# CM_CORE__L3INIT register map
Vendor: Texas Instruments
Peripheral module from a debugger description file (folder DRA74xP_75xP_76xP_77xP).
Registers are 32-bit, access per field, reset 0x70000 unless marked. A register's access mark holds for its fields unless they carry their own. Offsets are as the file gives them; lines under a group give offsets from that group; [hi:lo] are bit positions; {n}, {i} and the like mark numbered series; 'fields as' and 'values as' point back to an identical list; <NAME> marks a mode.

## CM_CORE__L3INIT
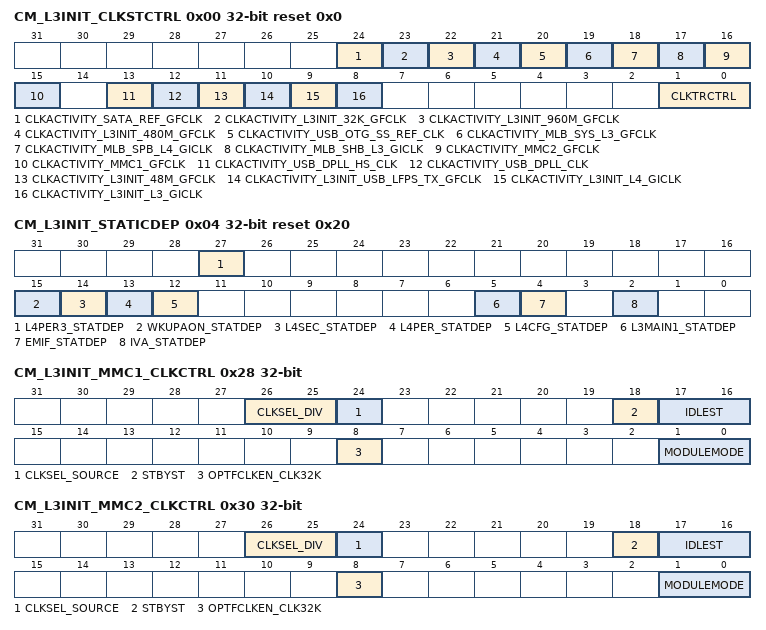
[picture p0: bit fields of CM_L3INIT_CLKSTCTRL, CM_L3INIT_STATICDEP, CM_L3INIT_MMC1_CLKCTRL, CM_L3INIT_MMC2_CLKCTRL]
0x00 CM_L3INIT_CLKSTCTRL reset 0x0 — This register enables the domain power state transition. It controls the HW supervised domain power state transition between ON-ACTIVE and ON-INACTIVE states. It also hold one status bit per clock input of the domain.
  [24] CLKACTIVITY_SATA_REF_GFCLK ro — This field indicates the state of the SATA_REF_GFCLK clock in the domain. [warm reset insensitive]
    0=INACT (Corresponding clock is definitely gated); 1=ACT (Corresponding clock is running or gating/ungating transition is on-going)
  [23] CLKACTIVITY_L3INIT_32K_GFCLK ro — This field indicates the state of the L3INIT_32K_FCLK clock in the domain. [warm reset insensitive]
    values as CLKACTIVITY_SATA_REF_GFCLK
  [22] CLKACTIVITY_L3INIT_960M_GFCLK ro — This field indicates the state of the L3INIT_960M_GFCLK clock in the domain. [warm reset insensitive]
    values as CLKACTIVITY_SATA_REF_GFCLK
  [21] CLKACTIVITY_L3INIT_480M_GFCLK ro — This field indicates the state of the L3INIT_480M_GFCLK clock in the domain. [warm reset insensitive]
    values as CLKACTIVITY_SATA_REF_GFCLK
  [20] CLKACTIVITY_USB_OTG_SS_REF_CLK ro — This field indicates the state of the USB_OTG_SS_REF_CLK clock in the domain. [warm reset insensitive]
    values as CLKACTIVITY_SATA_REF_GFCLK
  [19] CLKACTIVITY_MLB_SYS_L3_GFCLK ro — This field indicates the state of the MLB_SYS_L3_GFCLK clock in the domain. [warm reset insensitive]
    values as CLKACTIVITY_SATA_REF_GFCLK
  [18] CLKACTIVITY_MLB_SPB_L4_GICLK ro — This field indicates the state of the MLB_SPB_L4_GICLK clock in the domain. [warm reset insensitive]
    values as CLKACTIVITY_SATA_REF_GFCLK
  [17] CLKACTIVITY_MLB_SHB_L3_GICLK ro — This field indicates the state of the MLB_SHB_L3_GICLK clock in the domain. [warm reset insensitive]
    values as CLKACTIVITY_SATA_REF_GFCLK
  [16] CLKACTIVITY_MMC2_GFCLK ro — This field indicates the state of the MMC2 clock in the domain. [warm reset insensitive]
    values as CLKACTIVITY_SATA_REF_GFCLK
  [15] CLKACTIVITY_MMC1_GFCLK ro — This field indicates the state of the MMC1_GFCLK clock in the domain. [warm reset insensitive]
    values as CLKACTIVITY_SATA_REF_GFCLK
  [13] CLKACTIVITY_USB_DPLL_HS_CLK ro — This field indicates the state of the USB_DPLL_HS_CLK clock in the domain. [warm reset insensitive]
    values as CLKACTIVITY_SATA_REF_GFCLK
  [12] CLKACTIVITY_USB_DPLL_CLK ro — This field indicates the state of the USB_DPLL_CLK clock in the domain. [warm reset insensitive]
    values as CLKACTIVITY_SATA_REF_GFCLK
  [11] CLKACTIVITY_L3INIT_48M_GFCLK ro — This field indicates the state of the INIT_48M_GFCLK clock in the domain. [warm reset insensitive]
    values as CLKACTIVITY_SATA_REF_GFCLK
  [10] CLKACTIVITY_L3INIT_USB_LFPS_TX_GFCLK ro — This field indicates the state of the L3INIT_USB_LFPS_TX_GFCLK clock in the domain. [warm reset insensitive]
    values as CLKACTIVITY_SATA_REF_GFCLK
  [9] CLKACTIVITY_L3INIT_L4_GICLK ro — This field indicates the state of the L3INIT_L4_GICLK clock in the domain. [warm reset insensitive]
    values as CLKACTIVITY_SATA_REF_GFCLK
  [8] CLKACTIVITY_L3INIT_L3_GICLK ro — This field indicates the state of the L3INIT_L3_GICLK clock in the domain. [warm reset insensitive]
    values as CLKACTIVITY_SATA_REF_GFCLK
  [1:0] CLKTRCTRL rw — Controls the clock state transition of the L3INIT clock domain.
    0=NO_SLEEP (NO_SLEEP: Sleep transition cannot be initiated. Wakeup transition may however occur.); 1=SW_SLEEP (SW_SLEEP: Start a software forced sleep transition on the domain.); 2=SW_WKUP (SW_WKUP: Start a software forced wake-up transition on the domain.); 3=HW_AUTO (HW_AUTO: Automatic transition is enabled. Sleep and wakeup transition are based upon hardware conditions.)
0x04 CM_L3INIT_STATICDEP reset 0x20 — This register controls the static domain depedencies from L3INIT domain towards 'target' domains. It is relevant only for domain having system initiator(s).
  [27] L4PER3_STATDEP rw — Static dependency towards L4PER3 clock domain
    0=DISABLED (Dependency is disabled); 1=ENABLED (Dependency is enabled)
  [15] WKUPAON_STATDEP rw — Static dependency towards WKUPAON clock domain
    values as L4PER3_STATDEP
  [14] L4SEC_STATDEP rw — Static dependency towards L4SEC clock domain
    values as L4PER3_STATDEP
  [13] L4PER_STATDEP rw — Static dependency towards L4PER1 clock domain
    values as L4PER3_STATDEP
  [12] L4CFG_STATDEP rw — Static dependency towards L4CFG clock domain
    values as L4PER3_STATDEP
  [5] L3MAIN1_STATDEP ro — Static dependency towards L3MAIN1 clock domain
    1=ENABLED (Dependency is enabled)
  [4] EMIF_STATDEP rw — Static dependency towards EMIF clock domain
    values as L4PER3_STATDEP
  [2] IVA_STATDEP rw — Static dependency towards IVA clock domain
    values as L4PER3_STATDEP
0x08 CM_L3INIT_DYNAMICDEP ro reset 0x0 — This register controls the dynamic domain depedencies from L3INIT domain towards 'target' domains. It is relevant only for domain having OCP master port(s).
  [5] L3MAIN1_DYNDEP — Dynamic dependency towards L3MAIN1 clock domain
    0=DISABLED (Dependency is Disabled)
0x28 CM_L3INIT_MMC1_CLKCTRL — This register manages the MMC1 clocks.
  [26:25] CLKSEL_DIV rw — MMC1 clock divide ratio.
    0=DIV1 (MMC1 clock is divided by 1.); 1=DIV2 (MMC1 clock is divided by 2.); 2=DIV4 (MMC1 clock is divided by 4.)
  [24] CLKSEL_SOURCE rw — Selects the source of the functional clock.
    0=SEL_128M (128MHz clock derived from DPLL_PER is selected); 1=SEL_192M (192MHz clock derived from DPLL_PER is selected)
  [18] STBYST ro — Module standby status. [warm reset insensitive]
    0=FUNC (Module is functional (not in standby)); 1=STANDBY (Module is in standby)
  [17:16] IDLEST ro — Module idle status. [warm reset insensitive]
    0=FUNC (Module is fully functional, including OCP); 1=TRANS (Module is performing transition: wakeup, or sleep, or sleep abortion); 2=IDLE (Module is in Idle mode (only OCP part). It is functional if using separate functional clock); 3=DISABLE (Module is disabled and cannot be accessed)
  [8] OPTFCLKEN_CLK32K rw — MMC optional clock control: 32K CLK
    0=FCLK_DIS (Optional functional clock is disabled); 1=FCLK_EN (Optional functional clock is enabled)
  [1:0] MODULEMODE rw — Control the way mandatory clocks are managed.
    0=DISABLED (Module is disabled by SW. Any OCP access to module results in an error, except if resulting from a module wakeup (asynchronous wakeup).); 2=ENABLED (Module is explicitly enabled. Interface clock (if not used for functions) may be gated according to the clock domain state. Functional clocks are guarantied to stay present. As long as in this configuration, power domain sleep transition cannot happen.)
0x30 CM_L3INIT_MMC2_CLKCTRL — This register manages the MMC2 clocks.
  [26:25] CLKSEL_DIV rw — MMC2 clock divide ratio
    0=DIV1 (MMC2 clock is divided by 1.); 1=DIV2 (MMC2 clock is divided by 2.); 2=DIV4 (MMC2 clock is divided by 4.)
  [24] CLKSEL_SOURCE rw — Selects the source of the functional clock.
    values as CM_L3INIT_MMC1_CLKCTRL.CLKSEL_SOURCE
  [18] STBYST ro — Module standby status. [warm reset insensitive]
    values as CM_L3INIT_MMC1_CLKCTRL.STBYST
  [17:16] IDLEST ro — Module idle status. [warm reset insensitive]
    values as CM_L3INIT_MMC1_CLKCTRL.IDLEST
  [8] OPTFCLKEN_CLK32K rw — MMC optional clock control: 32K CLK
    values as CM_L3INIT_MMC1_CLKCTRL.OPTFCLKEN_CLK32K
  [1:0] MODULEMODE rw — Control the way mandatory clocks are managed.
    values as CM_L3INIT_MMC1_CLKCTRL.MODULEMODE
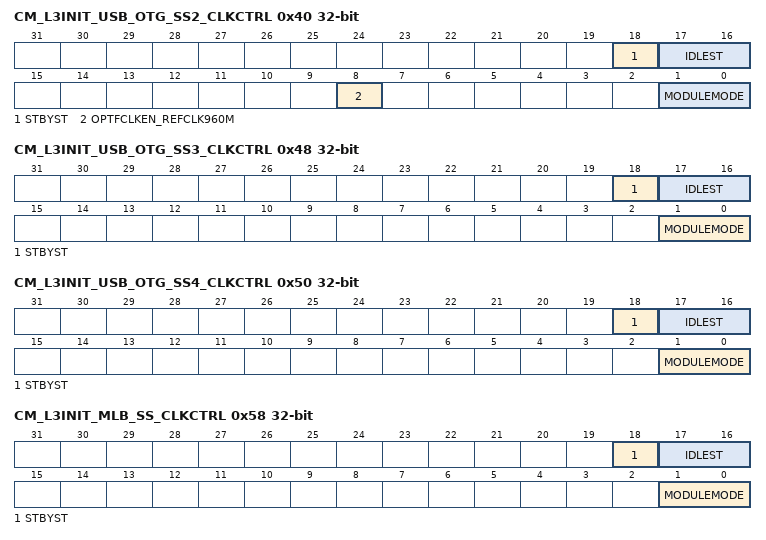
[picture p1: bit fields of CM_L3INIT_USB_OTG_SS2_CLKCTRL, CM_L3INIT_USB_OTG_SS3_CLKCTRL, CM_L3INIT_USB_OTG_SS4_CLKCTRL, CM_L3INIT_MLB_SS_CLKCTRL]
0x40 CM_L3INIT_USB_OTG_SS2_CLKCTRL — This register manages the USB_OTG_SS2 clocks.
  [18] STBYST ro — Module standby status. [warm reset insensitive]
    values as CM_L3INIT_MMC1_CLKCTRL.STBYST
  [17:16] IDLEST ro — Module idle status. [warm reset insensitive]
    values as CM_L3INIT_MMC1_CLKCTRL.IDLEST
  [8] OPTFCLKEN_REFCLK960M rw — USB_OTG_SS optional clock control: REFCLK960M (960MHz clock)
    values as CM_L3INIT_MMC1_CLKCTRL.OPTFCLKEN_CLK32K
  [1:0] MODULEMODE rw — Control the way mandatory clocks are managed.
    0=DISABLED (Module is disabled by SW. Any OCP access to module results in an error, except if resulting from a module wakeup (asynchronous wakeup).); 1=AUTO (Module is managed automatically by HW according to clock domain transition. A clock domain sleep transition put module into idle. A wakeup domain transition put it back into function. If CLKTRCTRL=3, any OCP access to module is always granted. Module clocks may be gated according to the clock domain state.)
0x48 CM_L3INIT_USB_OTG_SS3_CLKCTRL — This register manages the USB_OTG_SS3 clocks.
  [18] STBYST ro — Module standby status. [warm reset insensitive]
    values as CM_L3INIT_MMC1_CLKCTRL.STBYST
  [17:16] IDLEST ro — Module idle status. [warm reset insensitive]
    values as CM_L3INIT_MMC1_CLKCTRL.IDLEST
  [1:0] MODULEMODE rw — Control the way mandatory clocks are managed.
    values as CM_L3INIT_USB_OTG_SS2_CLKCTRL.MODULEMODE
0x50 CM_L3INIT_USB_OTG_SS4_CLKCTRL — This register manages the USB_OTG_SS4 clocks.
  fields as CM_L3INIT_USB_OTG_SS3_CLKCTRL
0x58 CM_L3INIT_MLB_SS_CLKCTRL — This register manages the MLBSS clocks.
  [18] STBYST ro — Module standby status. [warm reset insensitive]
    values as CM_L3INIT_MMC1_CLKCTRL.STBYST
  [17:16] IDLEST ro — Module idle status. [warm reset insensitive]
    values as CM_L3INIT_MMC1_CLKCTRL.IDLEST
  [1:0] MODULEMODE rw — Control the way mandatory clocks are managed.
    values as CM_L3INIT_MMC1_CLKCTRL.MODULEMODE
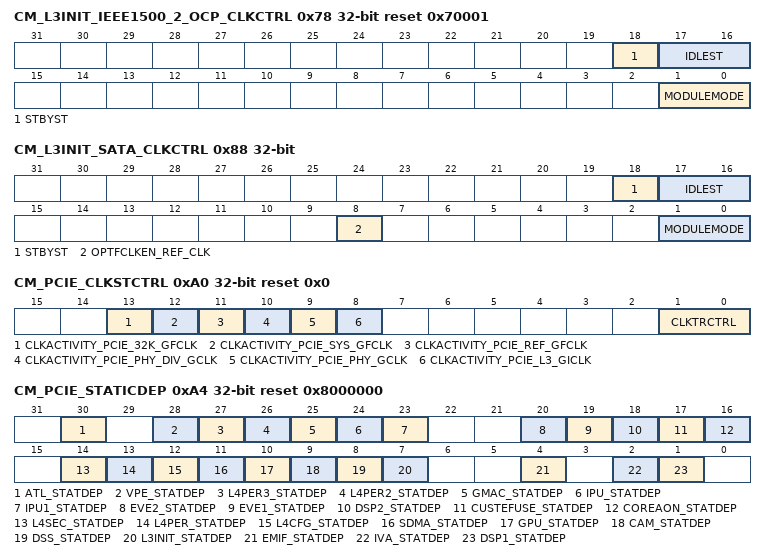
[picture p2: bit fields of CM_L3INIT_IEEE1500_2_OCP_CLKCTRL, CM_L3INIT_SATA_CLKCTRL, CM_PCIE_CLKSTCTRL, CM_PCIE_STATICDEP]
0x78 CM_L3INIT_IEEE1500_2_OCP_CLKCTRL ro reset 0x70001 — This register manages the IEE1500_2_OCP clocks.
  [18] STBYST — Module standby status. [warm reset insensitive]
    values as CM_L3INIT_MMC1_CLKCTRL.STBYST
  [17:16] IDLEST — Module idle status. [warm reset insensitive]
    values as CM_L3INIT_MMC1_CLKCTRL.IDLEST
  [1:0] MODULEMODE — Control the way mandatory clocks are managed.
    1=AUTO (Module is managed automatically by HW according to clock domain transition. A clock domain sleep transition put module into idle. A wakeup domain transition put it back into function. If CLKTRCTRL=3, any OCP access to module is always granted. Module clocks may be gated according to the clock domain state.)
0x88 CM_L3INIT_SATA_CLKCTRL — This register manages the SATA clocks.
  [18] STBYST ro — Module standby status. [warm reset insensitive]
    values as CM_L3INIT_MMC1_CLKCTRL.STBYST
  [17:16] IDLEST ro — Module idle status. [warm reset insensitive]
    values as CM_L3INIT_MMC1_CLKCTRL.IDLEST
  [8] OPTFCLKEN_REF_CLK rw — SATA optional clock control: REF_CLK (from SYS_CLK clock)
    values as CM_L3INIT_MMC1_CLKCTRL.OPTFCLKEN_CLK32K
  [1:0] MODULEMODE rw — Control the way mandatory clocks are managed.
    values as CM_L3INIT_MMC1_CLKCTRL.MODULEMODE
0xA0 CM_PCIE_CLKSTCTRL reset 0x0 — This register enables the domain power state transition. It controls the HW supervised domain power state transition between ON-ACTIVE and ON-INACTIVE states. It also hold one status bit per clock input of the domain.
  [13] CLKACTIVITY_PCIE_32K_GFCLK ro — This field indicates the state of the PCIE_32K_GFCLK clock in the domain. [warm reset insensitive]
    values as CM_L3INIT_CLKSTCTRL.CLKACTIVITY_SATA_REF_GFCLK
  [12] CLKACTIVITY_PCIE_SYS_GFCLK ro — This field indicates the state of the PCIE_SYS_GFCLK clock in the domain. [warm reset insensitive]
    values as CM_L3INIT_CLKSTCTRL.CLKACTIVITY_SATA_REF_GFCLK
  [11] CLKACTIVITY_PCIE_REF_GFCLK ro — This field indicates the state of the PCIE_REF_GFCLK clock in the domain. [warm reset insensitive]
    values as CM_L3INIT_CLKSTCTRL.CLKACTIVITY_SATA_REF_GFCLK
  [10] CLKACTIVITY_PCIE_PHY_DIV_GCLK ro — This field indicates the state of the PCIE_PHY_DIV_GCLK clock in the domain. [warm reset insensitive]
    values as CM_L3INIT_CLKSTCTRL.CLKACTIVITY_SATA_REF_GFCLK
  [9] CLKACTIVITY_PCIE_PHY_GCLK ro — This field indicates the state of the PCIE_PHY_GCLK clock in the domain. [warm reset insensitive]
    values as CM_L3INIT_CLKSTCTRL.CLKACTIVITY_SATA_REF_GFCLK
  [8] CLKACTIVITY_PCIE_L3_GICLK ro — This field indicates the state of the PCIE_L3_GICLK clock in the domain. [warm reset insensitive]
    values as CM_L3INIT_CLKSTCTRL.CLKACTIVITY_SATA_REF_GFCLK
  [1:0] CLKTRCTRL rw — Controls the clock state transition of the L3INIT clock domain.
    values as CM_L3INIT_CLKSTCTRL.CLKTRCTRL
0xA4 CM_PCIE_STATICDEP reset 0x8000000 — This register controls the static domain depedencies from PCIE domain towards 'target' domains. It is relevant only for domain having system initiator(s).
  [30] ATL_STATDEP rw — Static dependency towards ATL clock domain
    values as CM_L3INIT_STATICDEP.L4PER3_STATDEP
  [28] VPE_STATDEP rw — Static dependency towards VPE clock domain
    values as CM_L3INIT_STATICDEP.L4PER3_STATDEP
  [27] L4PER3_STATDEP rw — Static dependency towards L4PER3 clock domain
    values as CM_L3INIT_STATICDEP.L4PER3_STATDEP
  [26] L4PER2_STATDEP rw — Static dependency towards L4PER2 clock domain
    values as CM_L3INIT_STATICDEP.L4PER3_STATDEP
  [25] GMAC_STATDEP rw — Static dependency towards GMAC clock domain
    values as CM_L3INIT_STATICDEP.L4PER3_STATDEP
  [24] IPU_STATDEP rw — Static dependency towards IPU clock domain
    values as CM_L3INIT_STATICDEP.L4PER3_STATDEP
  [23] IPU1_STATDEP rw — Static dependency towards IPU1 clock domain
    values as CM_L3INIT_STATICDEP.L4PER3_STATDEP
  [20] EVE2_STATDEP rw — Static dependency towards EVE2 clock domain
    values as CM_L3INIT_STATICDEP.L4PER3_STATDEP
  [19] EVE1_STATDEP rw — Static dependency towards EVE1 clock domain
    values as CM_L3INIT_STATICDEP.L4PER3_STATDEP
  [18] DSP2_STATDEP rw — Static dependency towards DSP2 clock domain
    values as CM_L3INIT_STATICDEP.L4PER3_STATDEP
  [17] CUSTEFUSE_STATDEP ro — Static dependency towards CUSTEFUSE clock domain
    0=DISABLED (Dependency is disabled)
  [16] COREAON_STATDEP ro — Static dependency towards COREAON clock domain
    0=DISABLED (Dependency is disabled)
  [14] L4SEC_STATDEP rw — Static dependency towards L4SEC clock domain
    values as CM_L3INIT_STATICDEP.L4PER3_STATDEP
  [13] L4PER_STATDEP rw — Static dependency towards L4PER clock domain
    values as CM_L3INIT_STATICDEP.L4PER3_STATDEP
  [12] L4CFG_STATDEP rw — Static dependency towards L4CFG clock domain
    values as CM_L3INIT_STATICDEP.L4PER3_STATDEP
  [11] SDMA_STATDEP ro — Static dependency towards SDMA clock domain
    0=DISABLED (Dependency is disabled)
  [10] GPU_STATDEP rw — Static dependency towards GPU clock domain
    values as CM_L3INIT_STATICDEP.L4PER3_STATDEP
  [9] CAM_STATDEP rw — Static dependency towards CAM clock domain
    values as CM_L3INIT_STATICDEP.L4PER3_STATDEP
  [8] DSS_STATDEP rw — Static dependency towards DSS clock domain
    values as CM_L3INIT_STATICDEP.L4PER3_STATDEP
  [7] L3INIT_STATDEP rw — Static dependency towards L3INIT clock domain
    values as CM_L3INIT_STATICDEP.L4PER3_STATDEP
  [4] EMIF_STATDEP rw — Static dependency towards EMIF clock domain
    values as CM_L3INIT_STATICDEP.L4PER3_STATDEP
  [2] IVA_STATDEP rw — Static dependency towards IVA clock domain
    values as CM_L3INIT_STATICDEP.L4PER3_STATDEP
  [1] DSP1_STATDEP rw — Static dependency towards DSP1 clock domain
    values as CM_L3INIT_STATICDEP.L4PER3_STATDEP
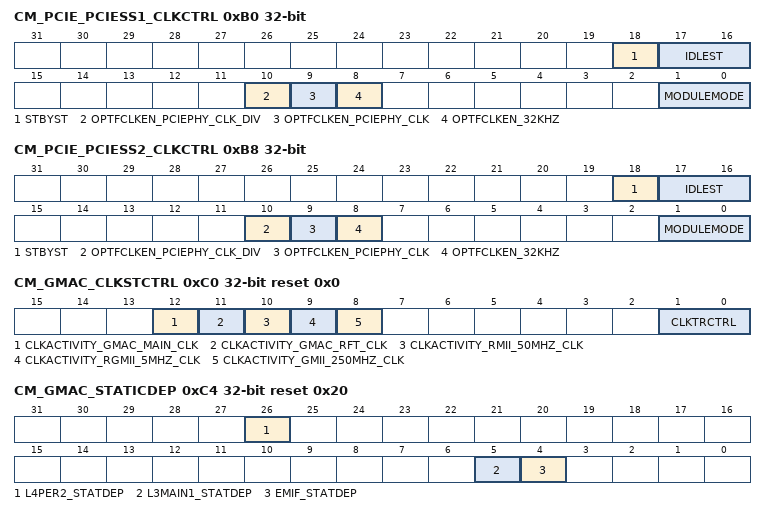
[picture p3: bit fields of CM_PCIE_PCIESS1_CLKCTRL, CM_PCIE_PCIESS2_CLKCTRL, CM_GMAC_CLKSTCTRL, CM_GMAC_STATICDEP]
0xB0 CM_PCIE_PCIESS1_CLKCTRL — This register manages the PCESS1 clocks.
  [18] STBYST ro — Module standby status. [warm reset insensitive]
    values as CM_L3INIT_MMC1_CLKCTRL.STBYST
  [17:16] IDLEST ro — Module idle status. [warm reset insensitive]
    values as CM_L3INIT_MMC1_CLKCTRL.IDLEST
  [10] OPTFCLKEN_PCIEPHY_CLK_DIV rw — PCIE PHY optional clock control
    values as CM_L3INIT_MMC1_CLKCTRL.OPTFCLKEN_CLK32K
  [9] OPTFCLKEN_PCIEPHY_CLK rw — PCIE PHY optional clock control
    values as CM_L3INIT_MMC1_CLKCTRL.OPTFCLKEN_CLK32K
  [8] OPTFCLKEN_32KHZ rw — PCIE PHY optional clock control
    values as CM_L3INIT_MMC1_CLKCTRL.OPTFCLKEN_CLK32K
  [1:0] MODULEMODE rw — Control the way mandatory clocks are managed.Note: In order to disable the APLL_PCIE, the user needs to disable PCIe_SSx (where x = 1 or 2) using the CM_PCIE_ PCIESSx_CLKCTRL[1:0] MODULEMODE registers. When PCIe_SS is disabled, the PRCM module automatically disables the APLL_PCIE. Please note that setting [1:0] MODE_SELECT bitfield to 0x0 does not disable the APLL_PCIE. .
    values as CM_L3INIT_MMC1_CLKCTRL.MODULEMODE
0xB8 CM_PCIE_PCIESS2_CLKCTRL — This register manages the PCESS2 clocks.
  fields as CM_PCIE_PCIESS1_CLKCTRL
0xC0 CM_GMAC_CLKSTCTRL reset 0x0 — This register enables the domain power state transition. It controls the HW supervised domain power state transition between ON-ACTIVE and ON-INACTIVE states. It also hold one status bit per clock input of the domain.
  [12] CLKACTIVITY_GMAC_MAIN_CLK ro — This field indicates the state of the GMAC_MAIN_CLK clock in the domain. [warm reset insensitive]
    values as CM_L3INIT_CLKSTCTRL.CLKACTIVITY_SATA_REF_GFCLK
  [11] CLKACTIVITY_GMAC_RFT_CLK ro — This field indicates the state of the GMAC_RFT_CLK clock in the domain. [warm reset insensitive]
    values as CM_L3INIT_CLKSTCTRL.CLKACTIVITY_SATA_REF_GFCLK
  [10] CLKACTIVITY_RMII_50MHZ_CLK ro — This field indicates the state of the RMII_50MHZ_CLK clock in the domain. [warm reset insensitive]
    values as CM_L3INIT_CLKSTCTRL.CLKACTIVITY_SATA_REF_GFCLK
  [9] CLKACTIVITY_RGMII_5MHZ_CLK ro — This field indicates the state of the RGMII_5MHZ_CLK clock in the domain. [warm reset insensitive]
    values as CM_L3INIT_CLKSTCTRL.CLKACTIVITY_SATA_REF_GFCLK
  [8] CLKACTIVITY_GMII_250MHZ_CLK ro — This field indicates the state of the GMII_250MHZ_CLK clock in the domain. [warm reset insensitive]
    values as CM_L3INIT_CLKSTCTRL.CLKACTIVITY_SATA_REF_GFCLK
  [1:0] CLKTRCTRL rw — WARNING: This bit field must not be programmed for SW_SLEEP or HW_AUTO for EEE mode. Controls the clock state transition of the GMAC clock domain.
    values as CM_L3INIT_CLKSTCTRL.CLKTRCTRL
0xC4 CM_GMAC_STATICDEP reset 0x20 — This register controls the static domain depedencies from GMAC domain towards 'target' domains. It is relevant only for domain having system initiator(s).
  [26] L4PER2_STATDEP rw — Static dependency towards L4PER2 clock domain
    values as CM_L3INIT_STATICDEP.L4PER3_STATDEP
  [5] L3MAIN1_STATDEP ro — Static dependency towards L3MAIN1 clock domain
    1=ENABLED (Dependency is enabled)
  [4] EMIF_STATDEP rw — Static dependency towards EMIF clock domain
    values as CM_L3INIT_STATICDEP.L4PER3_STATDEP
0xC8 CM_GMAC_DYNAMICDEP ro reset 0x0 — This register controls the dynamic domain depedencies from GMAC domain towards 'target' domains. It is relevant only for domain having OCP master port(s).
  [5] L3MAIN1_DYNDEP — Dynamic dependency towards L3MAIN1 clock domain
    0=DISABLED (Dependency is disabled)
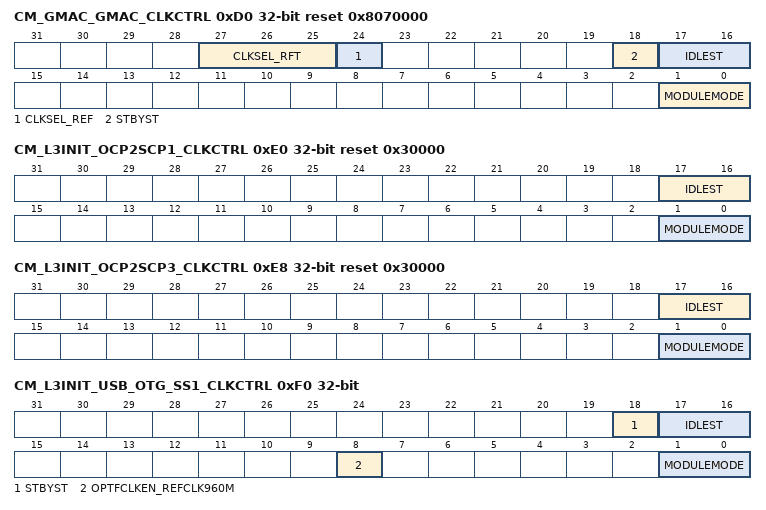
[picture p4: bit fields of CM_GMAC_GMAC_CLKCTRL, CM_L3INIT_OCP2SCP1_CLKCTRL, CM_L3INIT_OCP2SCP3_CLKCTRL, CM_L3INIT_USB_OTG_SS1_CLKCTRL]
0xD0 CM_GMAC_GMAC_CLKCTRL reset 0x8070000 — This register manages the GMAC clocks.
  [27:25] CLKSEL_RFT rw — Selects the source of the GMAC_RFT_CLK. [warm reset insensitive]
    0=VIDEO1_CLK_DPLL_VIDEO1_0 (Selects VIDEO1_CLK derived from DPLL_VIDEO1); 1=VIDEO2_CLK_DPLL_VIDEO2_1 (Selects VIDEO2_CLK derived from DPLL_VIDEO2); 2=PER_ABE_X1_GFCLK_DPLL_ABE_2 (Selects PER_ABE_X1_GFCLK derived from DPLL_ABE); 3=Selects_HDMI_CLK_derived_from_DPLL_HDMI; 4=Selects_L3_ICLK
  [24] CLKSEL_REF rw — Selects the source of the RMII_50MHZ_CLK functional clock. [warm reset insensitive]
    0=SEL_GMAC_RMII_HS_CLK (Selects GMAC_RMII_HS_CLK); 1=SEL_GMAC_RMII_CLK (Selects GMAC_RMII_CLK)
  [18] STBYST ro — Module standby status. [warm reset insensitive]
    values as CM_L3INIT_MMC1_CLKCTRL.STBYST
  [17:16] IDLEST ro — Module idle status. [warm reset insensitive]
    0=OCP_0 (Module is fully functional, including OCP); 1=Module is performing transition: wakeup, or sleep, or sleep abortion; 2=OCP_2 (Module is in Idle mode (only OCP part). It is functional if using separate functional clock); 3=Module is disabled and cannot be accessed
  [1:0] MODULEMODE rw — Controsl how mandatory clocks are managed. [warm reset insensitive]
    0=SW._OCP_0 (Module is disabled by SW. Any OCP access to module results in an error, except if resulting from a module wakeup (asynchronous wakeup).); 2=Module is explicitly enabled. Interface clock (if not used for functions) may be gated according to the clock domain state. Functional clocks are guarantied to stay present. As long as in this configuration, power domain sleep transition cannot happen.
0xE0 CM_L3INIT_OCP2SCP1_CLKCTRL reset 0x30000 — This register manages the OCP2SCP1 clocks and the optional clock of USB PHY.
  [17:16] IDLEST ro — Module idle status. [warm reset insensitive]
    values as CM_L3INIT_MMC1_CLKCTRL.IDLEST
  [1:0] MODULEMODE rw — Control the way mandatory clocks are managed.
    values as CM_L3INIT_USB_OTG_SS2_CLKCTRL.MODULEMODE
0xE8 CM_L3INIT_OCP2SCP3_CLKCTRL reset 0x30000 — This register manages the OCP2SCP3 clocks and the optional clock of USB PHY.
  fields as CM_L3INIT_OCP2SCP1_CLKCTRL
0xF0 CM_L3INIT_USB_OTG_SS1_CLKCTRL — This register manages the USB_OTG_SS1 clocks.
  fields as CM_L3INIT_USB_OTG_SS2_CLKCTRL
